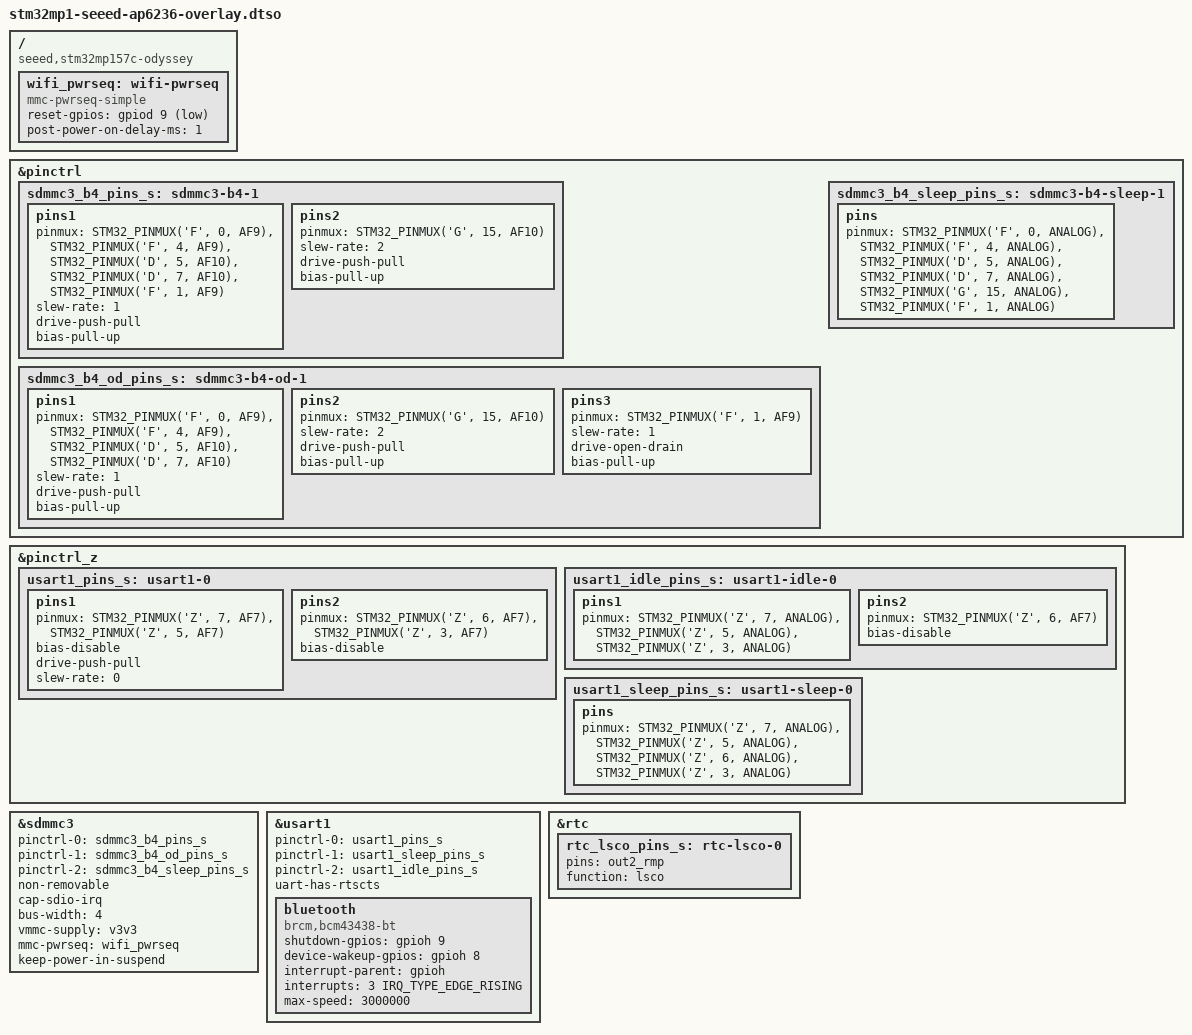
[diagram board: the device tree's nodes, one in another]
/*
 * Device tree overlay for ap6236
 */
#include "dt-bindings/gpio/gpio.h"
#include "dt-bindings/pinctrl/stm32-pinfunc.h"
#include "dt-bindings/interrupt-controller/irq.h"
/dts-v1/;
/plugin/;

/ {
	
	compatible = "seeed,stm32mp157c-odyssey", "seeed,npi-stm32mp1", "st,stm32mp157";
	fragment@0 {
		target = <&pinctrl>;
		__overlay__ {
			// sdmmc3 pin configure
			sdmmc3_b4_pins_s: sdmmc3-b4-1 {
				pins1 {
					pinmux = <STM32_PINMUX('F', 0, AF9)>, /* SDMMC3_D0 */
						<STM32_PINMUX('F', 4, AF9)>, /* SDMMC3_D1 */
						<STM32_PINMUX('D', 5, AF10)>, /* SDMMC3_D2 */
						<STM32_PINMUX('D', 7, AF10)>, /* SDMMC3_D3 */
						<STM32_PINMUX('F', 1, AF9)>; /* SDMMC3_CMD */
					slew-rate = <1>;
					drive-push-pull;
					bias-pull-up;
				};
				pins2 {
					pinmux = <STM32_PINMUX('G', 15, AF10)>; /* SDMMC3_CLK */
					slew-rate = <2>;
					drive-push-pull;
					bias-pull-up;
				};
			};

			sdmmc3_b4_od_pins_s: sdmmc3-b4-od-1 {
				pins1 {
					pinmux = <STM32_PINMUX('F', 0, AF9)>, /* SDMMC3_D0 */
							<STM32_PINMUX('F', 4, AF9)>, /* SDMMC3_D1 */
							<STM32_PINMUX('D', 5, AF10)>, /* SDMMC3_D2 */
							<STM32_PINMUX('D', 7, AF10)>; /* SDMMC3_D3 */
					slew-rate = <1>;
					drive-push-pull;
					bias-pull-up;
				};
				pins2 {
					pinmux = <STM32_PINMUX('G', 15, AF10)>; /* SDMMC3_CLK */
					slew-rate = <2>;
					drive-push-pull;
					bias-pull-up;
				};
				pins3 {
					pinmux = <STM32_PINMUX('F', 1, AF9)>; /* SDMMC3_CMD */
					slew-rate = <1>;
					drive-open-drain;
					bias-pull-up;
				};
			};

			sdmmc3_b4_sleep_pins_s: sdmmc3-b4-sleep-1 {
				pins {
					pinmux = <STM32_PINMUX('F', 0, ANALOG)>, /* SDMMC3_D0 */
							<STM32_PINMUX('F', 4, ANALOG)>, /* SDMMC3_D1 */
							<STM32_PINMUX('D', 5, ANALOG)>, /* SDMMC3_D2 */
							<STM32_PINMUX('D', 7, ANALOG)>, /* SDMMC3_D3 */
							<STM32_PINMUX('G', 15, ANALOG)>, /* SDMMC3_CK */
							<STM32_PINMUX('F', 1, ANALOG)>; /* SDMMC3_CMD */
				};
			};
		};
	};

	fragment@1 {
		target = <&pinctrl_z>;
		__overlay__ {
			// usart1 pin configure
			usart1_pins_s: usart1-0 {
				pins1 {
					pinmux = <STM32_PINMUX('Z', 7, AF7)>, /* USART1_TX */
						<STM32_PINMUX('Z', 5, AF7)>; /* USART1_RTS */
					bias-disable;
					drive-push-pull;
					slew-rate = <0>;
				};
				pins2 {
					pinmux = <STM32_PINMUX('Z', 6, AF7)>, /* USART1_RX */
						<STM32_PINMUX('Z', 3, AF7)>; /* USART1_CTS_NSS */
					bias-disable;
				};
			};

			usart1_idle_pins_s: usart1-idle-0 {
				pins1 {
					pinmux = <STM32_PINMUX('Z', 7, ANALOG)>, /* USART1_TX */
						<STM32_PINMUX('Z', 5, ANALOG)>, /* USART1_RTS */
						<STM32_PINMUX('Z', 3, ANALOG)>; /* USART1_CTS_NSS */
				};
				pins2 {
					pinmux = <STM32_PINMUX('Z', 6, AF7)>; /* USART1_RX */
					bias-disable;
				};
			};

			usart1_sleep_pins_s: usart1-sleep-0 {
				pins {
					pinmux = <STM32_PINMUX('Z', 7, ANALOG)>, /* USART1_TX */
						<STM32_PINMUX('Z', 5, ANALOG)>, /* USART1_RTS */
						<STM32_PINMUX('Z', 6, ANALOG)>, /* USART1_RX */
						<STM32_PINMUX('Z', 3, ANALOG)>; /* USART1_CTS_NSS */
				};
			};
		};
	};

	fragment@10 {
		target-path = "/";
		__overlay__ {
			wifi_pwrseq: wifi-pwrseq {
				compatible = "mmc-pwrseq-simple";
				reset-gpios = <&gpiod 9 GPIO_ACTIVE_LOW>;
				post-power-on-delay-ms = <1>;
			};
		};
	};
	/* Wifi */
	fragment@20 {
		target = <&sdmmc3>;
		__overlay__ {
			#address-cells = <1>;
			#size-cells = <0>;
			/* arm,primecell-periphid = <0x10153180>; */
			pinctrl-names = "default", "opendrain", "sleep";
			pinctrl-0 = <&sdmmc3_b4_pins_s>;
			pinctrl-1 = <&sdmmc3_b4_od_pins_s>;
			pinctrl-2 = <&sdmmc3_b4_sleep_pins_s>;
			non-removable;
			cap-sdio-irq;
			bus-width = <4>;
			vmmc-supply = <&v3v3>;
			mmc-pwrseq = <&wifi_pwrseq>;
			keep-power-in-suspend;
			status = "okay";
		};
	};

	/* Bluetooth */
	fragment@30 {
		target = <&usart1>;
		__overlay__ {
			pinctrl-names = "default", "sleep", "idle";
			pinctrl-0 = <&usart1_pins_s>;
			pinctrl-1 = <&usart1_sleep_pins_s>;
			pinctrl-2 = <&usart1_idle_pins_s>;
			uart-has-rtscts;
			status = "okay";

			bluetooth {
				compatible = "brcm,bcm43438-bt";
				shutdown-gpios = <&gpioh 9 GPIO_ACTIVE_HIGH>;
				device-wakeup-gpios = <&gpioh 8 GPIO_ACTIVE_HIGH>;
				interrupt-parent = <&gpioh>;
				interrupts = <3 IRQ_TYPE_EDGE_RISING>;
				interrupt-names = "host-wakeup";
				max-speed = <3000000>;
			};
		};
	};
    
	/* Configure RTC LSCO on OUT2_RMP for the AP6236 32.768 kHz LPO clock. */
	fragment@40 {
		target = <&rtc>;
		__overlay__ {
			status = "okay";

			rtc_lsco_pins_s: rtc-lsco-0 {
				pins = "out2_rmp";
				function = "lsco";
			};
		};
	};
};

